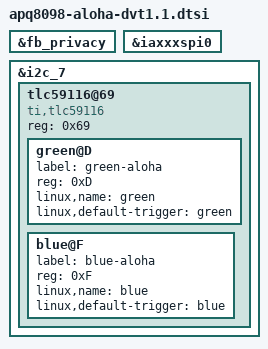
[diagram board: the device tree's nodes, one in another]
/* Copyright (c) 2018, Facebook Inc. All rights reserved.
 *
 * This program is free software; you can redistribute it and/or modify
 * it under the terms of the GNU General Public License version 2 and
 * only version 2 as published by the Free Software Foundation.
 *
 * This program is distributed in the hope that it will be useful,
 * but WITHOUT ANY WARRANTY; without even the implied warranty of
 * MERCHANTABILITY or FITNESS FOR A PARTICULAR PURPOSE.  See the
 * GNU General Public License for more details.
 */

#include "apq8098-aloha-evt2.dtsi"

&fb_privacy {
	/delete-property/ fb,legacy-hardware;
};

&iaxxxspi0 {
	/delete-property/ iaxxx,suspend-on-privacy;
};

&i2c_7 {
	tlc59116@69 {
		#address-cells = <1>;
		#size-cells = <0>;
		compatible = "ti,tlc59116";
		reg = <0x69>;

		green@D {
			label = "green-aloha";
			reg = <0xD>;
			linux,name = "green";
			linux,default-trigger = "green";
		};

		blue@F {
			label = "blue-aloha";
			reg = <0xF>;
			linux,name = "blue";
			linux,default-trigger = "blue";
		};
	};
};
